# ESP32-H21 register map
Vendor: ESPRESSIF SYSTEMS (SHANGHAI) CO., LTD.; Series: ESP32 H-Series; File version: 1
CPU: RV32IMAC r0p0, little endian, no MPU, no FPU, 0 interrupt priority bits
Address unit: 32 bits
Registers are 32-bit, read-write, reset 0x0 unless marked. A register's access mark holds for its fields unless they carry their own. Offsets are from the block's base; [hi:lo] are bit positions; {n}, {i} and the like mark numbered series.

## SPI0 (part 1 of 2) — SPI (Serial Peripheral Interface) Controller 0
Base 0x60002000
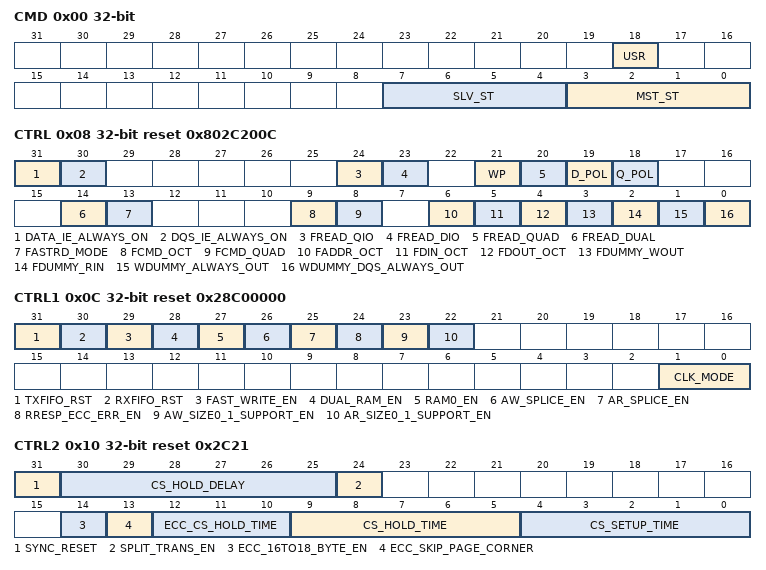
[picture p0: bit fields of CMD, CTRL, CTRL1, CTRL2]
0x00 CMD ro — SPI0 FSM status register
  [18] USR — SPI0 USR_CMD start bit, only used when SPI_MEM_AXI_REQ_EN is cleared. An operation will be triggered when the bit is set. The bit will be cleared once the operation done.1: enable 0: disable.
  [7:4] SLV_ST — The current status of SPI0 slave FSM: mspi_st. 0: idle state, 1: preparation state, 2: send command state, 3: send address state, 4: wait state, 5: read data state, 6:write data state, 7: done state, 8: read data end state.
  [3:0] MST_ST — The current status of SPI0 master FSM: spi0_mst_st. 0: idle state, 1:SPI0_GRANT , 2: program/erase suspend state, 3: SPI0 read data state, 4: wait cache/EDMA sent data is stored in SPI0 TX FIFO, 5: SPI0 write data state.
0x04 ADDR ro — SPI0 USR_CMD address register
  [31:0] USR_ADDR_VALUE — In SPI0 USR_CMD mode when SPI_MEM_USR is set, it is the memory address.
0x08 CTRL access per field reset 0x802C200C — SPI0 control register.
  [31] DATA_IE_ALWAYS_ON rw — When accesses to flash, 1: the IE signals of pads connected to SPI_IO[7:0] are always 1. 0: Others.
  [30] DQS_IE_ALWAYS_ON ro — When accesses to flash, 1: the IE signals of pads connected to SPI_DQS are always 1. 0: Others.
  [24] FREAD_QIO rw — In the read operations address phase and read-data phase apply 4 signals. 1: enable 0: disable.
  [23] FREAD_DIO rw — In the read operations address phase and read-data phase apply 2 signals. 1: enable 0: disable.
  [21] WP rw — Write protect signal output when SPI is idle. 1: output high, 0: output low.
  [20] FREAD_QUAD rw — In the read operations read-data phase apply 4 signals. 1: enable 0: disable.
  [19] D_POL rw — The bit is used to set MOSI line polarity, 1: high 0, low
  [18] Q_POL rw — The bit is used to set MISO line polarity, 1: high 0, low
  [14] FREAD_DUAL rw — In the read operations, read-data phase apply 2 signals. 1: enable 0: disable.
  [13] FASTRD_MODE rw — This bit enable the bits: SPI_MEM_FREAD_QIO, SPI_MEM_FREAD_DIO, SPI_MEM_FREAD_QOUT and SPI_MEM_FREAD_DOUT. 1: enable 0: disable.
  [9] FCMD_OCT ro — Apply 8 signals during command phase 1:enable 0: disable
  [8] FCMD_QUAD rw — Apply 4 signals during command phase 1:enable 0: disable
  [6] FADDR_OCT ro — Apply 8 signals during address phase 1:enable 0: disable
  [5] FDIN_OCT ro — Apply 8 signals during read-data phase 1:enable 0: disable
  [4] FDOUT_OCT ro — Apply 8 signals during write-data phase 1:enable 0: disable
  [3] FDUMMY_WOUT rw — In an MSPI write data transfer when accesses to flash, the level of SPI_IO[7:0] is output by the MSPI controller in the second half part of dummy phase. It is used to pre-drive flash.
  [2] FDUMMY_RIN rw — In an MSPI read data transfer when accesses to flash, the level of SPI_IO[7:0] is output by the MSPI controller in the first half part of dummy phase. It is used to mask invalid SPI_DQS in the half part of dummy phase.
  [1] WDUMMY_ALWAYS_OUT rw — In the dummy phase of an MSPI write data transfer when accesses to flash, the level of SPI_IO[7:0] is output by the MSPI controller.
  [0] WDUMMY_DQS_ALWAYS_OUT ro — In the dummy phase of an MSPI write data transfer when accesses to flash, the level of SPI_DQS is output by the MSPI controller.
0x0C CTRL1 access per field reset 0x28C00000 — SPI0 control1 register.
  [31] TXFIFO_RST wo — The synchronous reset signal for SPI0 TX AFIFO and all the AES_MSPI SYNC FIFO to send signals to AXI. Set this bit to reset these FIFO.
  [30] RXFIFO_RST wo — The synchronous reset signal for SPI0 RX AFIFO and all the AES_MSPI SYNC FIFO to receive signals from AXI. Set this bit to reset these FIFO.
  [29] FAST_WRITE_EN rw — Set this bit to write data faster, do not wait write data has been stored in tx_bus_fifo_l2. It will wait 4*T_clk_ctrl to insure the write data has been stored in tx_bus_fifo_l2.
  [28] DUAL_RAM_EN ro — Set this bit to enable DUAL-RAM mode, EXT_RAM0 and EXT_RAM1 will be accessed at the same time.
  [27] RAM0_EN ro — When SPI_MEM_DUAL_RAM_EN is 0 and SPI_MEM_RAM0_EN is 1, only EXT_RAM0 will be accessed. When SPI_MEM_DUAL_RAM_EN is 0 and SPI_MEM_RAM0_EN is 0, only EXT_RAM1 will be accessed. When SPI_MEM_DUAL_RAM_EN is 1, EXT_RAM0 and EXT_RAM1 will be accessed at the same time.
  [26] AW_SPLICE_EN ro — Set this bit to enable AXI Write Splice-transfer.
  [25] AR_SPLICE_EN ro — Set this bit to enable AXI Read Splice-transfer.
  [24] RRESP_ECC_ERR_EN rw — 1: RRESP is SLV_ERR when there is a ECC error in AXI read data. 0: RRESP is OKAY when there is a ECC error in AXI read data. The ECC error information is recorded in SPI_MEM_ECC_ERR_ADDR_REG.
  [23] AW_SIZE0_1_SUPPORT_EN rw — 1: MSPI supports AWSIZE 0~3. 0: When AWSIZE 0~1, MSPI reply SLV_ERR.
  [22] AR_SIZE0_1_SUPPORT_EN rw — 1: MSPI supports ARSIZE 0~3. When ARSIZE =0~2, MSPI read address is 4*n and reply the real AXI read data back. 0: When ARSIZE 0~1, MSPI reply SLV_ERR.
  [1:0] CLK_MODE rw — SPI clock mode bits. 0: SPI clock is off when CS inactive 1: SPI clock is delayed one cycle after CS inactive 2: SPI clock is delayed two cycles after CS inactive 3: SPI clock is alwasy on.
0x10 CTRL2 access per field reset 0x2C21 — SPI0 control2 register.
  [31] SYNC_RESET wo — The spi0_mst_st and spi0_slv_st will be reset.
  [30:25] CS_HOLD_DELAY rw — These bits are used to set the minimum CS high time tSHSL between SPI burst transfer when accesses to flash. tSHSL is (SPI_MEM_CS_HOLD_DELAY[5:0] + 1) MSPI core clock cycles.
  [24] SPLIT_TRANS_EN ro — Set this bit to enable SPI0 split one AXI read flash transfer into two SPI transfers when one transfer will cross flash or EXT_RAM page corner, valid no matter whether there is an ECC region or not.
  [14] ECC_16TO18_BYTE_EN ro — Set this bit to enable SPI0 and SPI1 ECC 16 bytes data with 2 ECC bytes mode when accesses flash.
  [13] ECC_SKIP_PAGE_CORNER ro — 1: SPI0 and SPI1 skip page corner when accesses flash. 0: Not skip page corner when accesses flash.
  [12:10] ECC_CS_HOLD_TIME ro — SPI_MEM_CS_HOLD_TIME + SPI_MEM_ECC_CS_HOLD_TIME is the SPI0 CS hold cycle in ECC mode when accessed flash.
  [9:5] CS_HOLD_TIME rw — SPI CS signal is delayed to inactive by SPI bus clock, this bits are combined with SPI_MEM_CS_HOLD bit.
  [4:0] CS_SETUP_TIME rw — (cycles-1) of prepare phase by SPI Bus clock, this bits are combined with SPI_MEM_CS_SETUP bit.
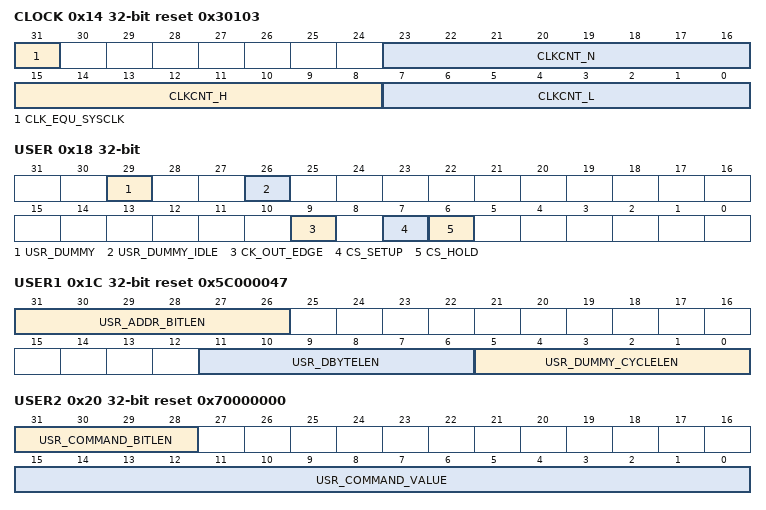
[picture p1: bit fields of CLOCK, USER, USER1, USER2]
0x14 CLOCK reset 0x30103 — SPI clock division control register.
  [31] CLK_EQU_SYSCLK — 1: 1-division mode, the frequency of SPI bus clock equals to that of MSPI module clock.
  [23:16] CLKCNT_N — In the master mode it is the divider of spi_mem_clk. So spi_mem_clk frequency is system/(SPI_MEM_CLKCNT_N+1)
  [15:8] CLKCNT_H — In the master mode it must be floor((SPI_MEM_CLKCNT_N+1)/2-1).
  [7:0] CLKCNT_L — In the master mode it must be equal to SPI_MEM_CLKCNT_N.
0x18 USER — SPI0 user register.
  [29] USR_DUMMY — This bit enable the dummy phase of an operation.
  [26] USR_DUMMY_IDLE — spi clock is disable in dummy phase when the bit is enable.
  [9] CK_OUT_EDGE — The bit combined with SPI_MEM_CK_IDLE_EDGE bit to control SPI clock mode 0~3.
  [7] CS_SETUP — spi cs is enable when spi is in prepare phase. 1: enable 0: disable.
  [6] CS_HOLD — spi cs keep low when spi is in done phase. 1: enable 0: disable.
0x1C USER1 access per field reset 0x5C000047 — SPI0 user1 register.
  [31:26] USR_ADDR_BITLEN rw — The length in bits of address phase. The register value shall be (bit_num-1).
  [11:6] USR_DBYTELEN ro — SPI0 USR_CMD read or write data byte length -1
  [5:0] USR_DUMMY_CYCLELEN rw — The length in spi_mem_clk cycles of dummy phase. The register value shall be (cycle_num-1).
0x20 USER2 reset 0x70000000 — SPI0 user2 register.
  [31:28] USR_COMMAND_BITLEN — The length in bits of command phase. The register value shall be (bit_num-1)
  [15:0] USR_COMMAND_VALUE — The value of command.
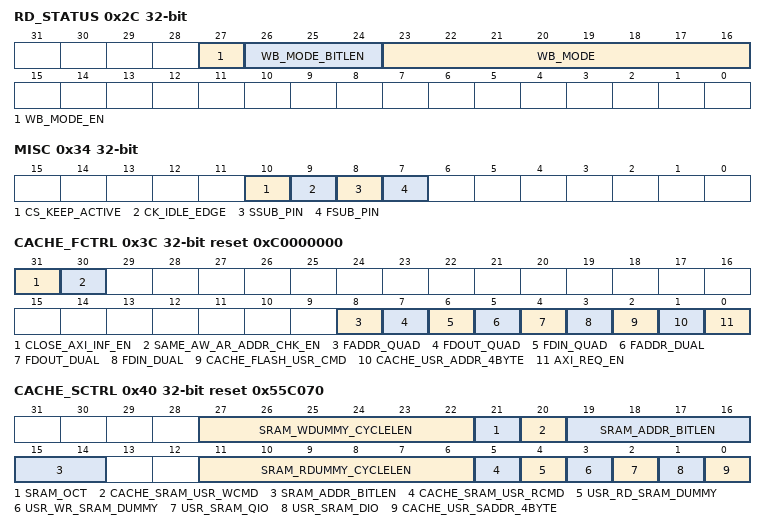
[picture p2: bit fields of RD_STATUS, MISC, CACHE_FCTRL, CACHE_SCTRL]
0x2C RD_STATUS — SPI0 read control register.
  [27] WB_MODE_EN — Mode bits is valid while this bit is enable. 1: enable 0: disable.
  [26:24] WB_MODE_BITLEN — Mode bits length for flash fast read mode.
  [23:16] WB_MODE — Mode bits in the flash fast read mode it is combined with spi_mem_fastrd_mode bit.
0x34 MISC access per field — SPI0 misc register
  [10] CS_KEEP_ACTIVE rw — SPI_CS line keep low when the bit is set.
  [9] CK_IDLE_EDGE rw — 1: SPI_CLK line is high when idle 0: spi clk line is low when idle
  [8] SSUB_PIN ro — For SPI0, sram is connected to SUBPINs.
  [7] FSUB_PIN ro — For SPI0, flash is connected to SUBPINs.
0x3C CACHE_FCTRL access per field reset 0xC0000000 — SPI0 bit mode control register.
  [31] CLOSE_AXI_INF_EN rw — Set this bit to close AXI read/write transfer to MSPI, which means that only SLV_ERR will be replied to BRESP/RRESP.
  [30] SAME_AW_AR_ADDR_CHK_EN ro — Set this bit to check AXI read/write the same address region.
  [8] FADDR_QUAD rw — For SPI0 flash, address phase apply 4 signals. 1: enable 0: disable. The bit is the same with spi_mem_fread_qio.
  [7] FDOUT_QUAD rw — For SPI0 flash, dout phase apply 4 signals. 1: enable 0: disable. The bit is the same with spi_mem_fread_qio.
  [6] FDIN_QUAD rw — For SPI0 flash, din phase apply 4 signals. 1: enable 0: disable. The bit is the same with spi_mem_fread_qio.
  [5] FADDR_DUAL rw — For SPI0 flash, address phase apply 2 signals. 1: enable 0: disable. The bit is the same with spi_mem_fread_dio.
  [4] FDOUT_DUAL rw — For SPI0 flash, dout phase apply 2 signals. 1: enable 0: disable. The bit is the same with spi_mem_fread_dio.
  [3] FDIN_DUAL rw — For SPI0 flash, din phase apply 2 signals. 1: enable 0: disable. The bit is the same with spi_mem_fread_dio.
  [2] CACHE_FLASH_USR_CMD rw — For SPI0, cache read flash for user define command, 1: enable, 0:disable.
  [1] CACHE_USR_ADDR_4BYTE rw — For SPI0, cache read flash with 4 bytes address, 1: enable, 0:disable.
  [0] AXI_REQ_EN rw — For SPI0, AXI master access enable, 1: enable, 0:disable.
0x40 CACHE_SCTRL ro reset 0x55C070 — SPI0 external RAM control register
  [27:22] SRAM_WDUMMY_CYCLELEN — For SPI0, In the external RAM mode, it is the length in bits of write dummy phase. The register value shall be (bit_num-1).
  [21] SRAM_OCT — reserved
  [20] CACHE_SRAM_USR_WCMD — For SPI0, In the external RAM mode cache write sram for user define command
  [19:14] SRAM_ADDR_BITLEN — For SPI0, In the external RAM mode, it is the length in bits of address phase. The register value shall be (bit_num-1).
  [11:6] SRAM_RDUMMY_CYCLELEN — For SPI0, In the external RAM mode, it is the length in bits of read dummy phase. The register value shall be (bit_num-1).
  [5] CACHE_SRAM_USR_RCMD — For SPI0, In the external RAM mode cache read external RAM for user define command.
  [4] USR_RD_SRAM_DUMMY — For SPI0, In the external RAM mode, it is the enable bit of dummy phase for read operations.
  [3] USR_WR_SRAM_DUMMY — For SPI0, In the external RAM mode, it is the enable bit of dummy phase for write operations.
  [2] USR_SRAM_QIO — For SPI0, In the external RAM mode, spi quad I/O mode enable, 1: enable, 0:disable
  [1] USR_SRAM_DIO — For SPI0, In the external RAM mode, spi dual I/O mode enable, 1: enable, 0:disable
  [0] CACHE_USR_SADDR_4BYTE — For SPI0, In the external RAM mode, cache read flash with 4 bytes command, 1: enable, 0:disable.
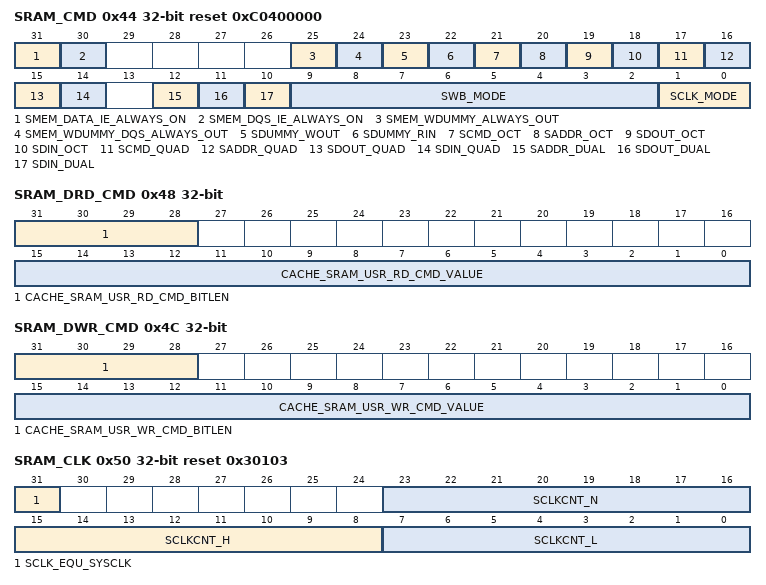
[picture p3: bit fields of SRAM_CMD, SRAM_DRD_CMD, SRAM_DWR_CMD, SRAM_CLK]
0x44 SRAM_CMD access per field reset 0xC0400000 — SPI0 external RAM mode control register
  [31] SMEM_DATA_IE_ALWAYS_ON ro — When accesses to external RAM, 1: the IE signals of pads connected to SPI_IO[7:0] are always 1. 0: Others.
  [30] SMEM_DQS_IE_ALWAYS_ON ro — When accesses to external RAM, 1: the IE signals of pads connected to SPI_DQS are always 1. 0: Others.
  [25] SMEM_WDUMMY_ALWAYS_OUT ro — In the dummy phase of an MSPI write data transfer when accesses to external RAM, the level of SPI_IO[7:0] is output by the MSPI controller.
  [24] SMEM_WDUMMY_DQS_ALWAYS_OUT ro — In the dummy phase of an MSPI write data transfer when accesses to external RAM, the level of SPI_DQS is output by the MSPI controller.
  [23] SDUMMY_WOUT ro — In the dummy phase of a MSPI write data transfer when accesses to external RAM, the signal level of SPI bus is output by the MSPI controller.
  [22] SDUMMY_RIN rw — In the dummy phase of a MSPI read data transfer when accesses to external RAM, the signal level of SPI bus is output by the MSPI controller.
  [21] SCMD_OCT ro — For SPI0 external RAM , cmd phase apply 8 signals. 1: enable 0: disable.
  [20] SADDR_OCT ro — For SPI0 external RAM , address phase apply 4 signals. 1: enable 0: disable.
  [19] SDOUT_OCT ro — For SPI0 external RAM , dout phase apply 8 signals. 1: enable 0: disable.
  [18] SDIN_OCT ro — For SPI0 external RAM , din phase apply 8 signals. 1: enable 0: disable.
  [17] SCMD_QUAD ro — For SPI0 external RAM , cmd phase apply 4 signals. 1: enable 0: disable. The bit is the same with spi_mem_usr_sram_qio.
  [16] SADDR_QUAD ro — For SPI0 external RAM , address phase apply 4 signals. 1: enable 0: disable. The bit is the same with spi_mem_usr_sram_qio.
  [15] SDOUT_QUAD ro — For SPI0 external RAM , dout phase apply 4 signals. 1: enable 0: disable. The bit is the same with spi_mem_usr_sram_qio.
  [14] SDIN_QUAD ro — For SPI0 external RAM , din phase apply 4 signals. 1: enable 0: disable. The bit is the same with spi_mem_usr_sram_qio.
  [12] SADDR_DUAL ro — For SPI0 external RAM , address phase apply 2 signals. 1: enable 0: disable. The bit is the same with spi_mem_usr_sram_dio.
  [11] SDOUT_DUAL ro — For SPI0 external RAM , dout phase apply 2 signals. 1: enable 0: disable. The bit is the same with spi_mem_usr_sram_dio.
  [10] SDIN_DUAL ro — For SPI0 external RAM , din phase apply 2 signals. 1: enable 0: disable. The bit is the same with spi_mem_usr_sram_dio.
  [9:2] SWB_MODE ro — Mode bits in the external RAM fast read mode it is combined with spi_mem_fastrd_mode bit.
  [1:0] SCLK_MODE ro — SPI clock mode bits. 0: SPI clock is off when CS inactive 1: SPI clock is delayed one cycle after CS inactive 2: SPI clock is delayed two cycles after CS inactive 3: SPI clock is always on.
0x48 SRAM_DRD_CMD ro — SPI0 external RAM DDR read command control register
  [31:28] CACHE_SRAM_USR_RD_CMD_BITLEN — For SPI0,When cache mode is enable it is the length in bits of command phase for sram. The register value shall be (bit_num-1).
  [15:0] CACHE_SRAM_USR_RD_CMD_VALUE — For SPI0,When cache mode is enable it is the read command value of command phase for sram.
0x4C SRAM_DWR_CMD ro — SPI0 external RAM DDR write command control register
  [31:28] CACHE_SRAM_USR_WR_CMD_BITLEN — For SPI0,When cache mode is enable it is the in bits of command phase for sram. The register value shall be (bit_num-1).
  [15:0] CACHE_SRAM_USR_WR_CMD_VALUE — For SPI0,When cache mode is enable it is the write command value of command phase for sram.
0x50 SRAM_CLK ro reset 0x30103 — SPI0 external RAM clock control register
  [31] SCLK_EQU_SYSCLK — For SPI0 external RAM interface, 1: spi_mem_clk is eqaul to system 0: spi_mem_clk is divided from system clock.
  [23:16] SCLKCNT_N — For SPI0 external RAM interface, it is the divider of spi_mem_clk. So spi_mem_clk frequency is system/(SPI_MEM_SCLKCNT_N+1)
  [15:8] SCLKCNT_H — For SPI0 external RAM interface, it must be floor((SPI_MEM_SCLKCNT_N+1)/2-1).
  [7:0] SCLKCNT_L — For SPI0 external RAM interface, it must be equal to SPI_MEM_SCLKCNT_N.
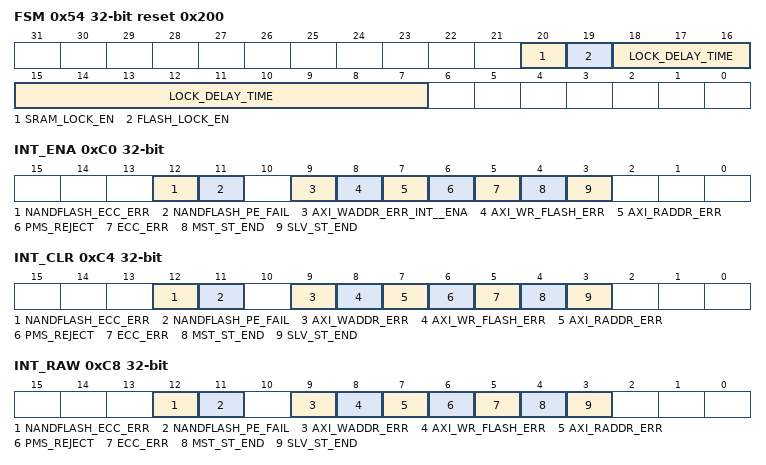
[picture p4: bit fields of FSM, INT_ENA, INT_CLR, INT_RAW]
0x54 FSM reset 0x200 — SPI0 FSM status register
  [20] SRAM_LOCK_EN — The lock enable for external RAM to lock spi0 trans req.1: Enable. 0: Disable.
  [19] FLASH_LOCK_EN — The lock enable for FLASH to lock spi0 trans req.1: Enable. 0: Disable.
  [18:7] LOCK_DELAY_TIME — The lock delay time of SPI0/1 arbiter by spi0_slv_st, after PER is sent by SPI1.
0xC0 INT_ENA access per field — SPI0 interrupt enable register
  [12] NANDFLASH_ECC_ERR ro — The enable bit for SPI_MEM_NANDFLASH_ECC_ERR_INT interrupt.
  [11] NANDFLASH_PE_FAIL ro — The enable bit for SPI_MEM_NANDFLASH_PE_FAIL_INT interrupt.
  [9] AXI_WADDR_ERR_INT__ENA ro — The enable bit for SPI_MEM_AXI_WADDR_ERR_INT interrupt.
  [8] AXI_WR_FLASH_ERR ro — The enable bit for SPI_MEM_AXI_WR_FALSH_ERR_INT interrupt.
  [7] AXI_RADDR_ERR rw — The enable bit for SPI_MEM_AXI_RADDR_ERR_INT interrupt.
  [6] PMS_REJECT rw — The enable bit for SPI_MEM_PMS_REJECT_INT interrupt.
  [5] ECC_ERR ro — The enable bit for SPI_MEM_ECC_ERR_INT interrupt.
  [4] MST_ST_END rw — The enable bit for SPI_MEM_MST_ST_END_INT interrupt.
  [3] SLV_ST_END rw — The enable bit for SPI_MEM_SLV_ST_END_INT interrupt.
0xC4 INT_CLR access per field — SPI0 interrupt clear register
  [12] NANDFLASH_ECC_ERR ro write-1-clears — The clear bit for SPI_MEM_NANDFLASH_ECC_ERR_INT interrupt.
  [11] NANDFLASH_PE_FAIL ro write-1-clears — The clear bit for SPI_MEM_NANDFLASH_PE_FAIL_INT interrupt.
  [9] AXI_WADDR_ERR ro write-1-clears — The clear bit for SPI_MEM_AXI_WADDR_ERR_INT interrupt.
  [8] AXI_WR_FLASH_ERR ro write-1-clears — The clear bit for SPI_MEM_AXI_WR_FALSH_ERR_INT interrupt.
  [7] AXI_RADDR_ERR wo write-1-clears — The clear bit for SPI_MEM_AXI_RADDR_ERR_INT interrupt.
  [6] PMS_REJECT wo write-1-clears — The clear bit for SPI_MEM_PMS_REJECT_INT interrupt.
  [5] ECC_ERR ro write-1-clears — The clear bit for SPI_MEM_ECC_ERR_INT interrupt.
  [4] MST_ST_END wo write-1-clears — The clear bit for SPI_MEM_MST_ST_END_INT interrupt.
  [3] SLV_ST_END wo write-1-clears — The clear bit for SPI_MEM_SLV_ST_END_INT interrupt.
0xC8 INT_RAW access per field — SPI0 interrupt raw register
  [12] NANDFLASH_ECC_ERR ro — The raw bit for SPI_MEM_NANDFLASH_ECC_ERR_INT interrupt. 1: Triggered when NAND FLASH SPI SEQ found ECCS bits is err when RDSR. 0: Others.
  [11] NANDFLASH_PE_FAIL ro — The raw bit for SPI_MEM_NANDFLASH_PE_FAIL_INT interrupt. 1: Triggered when NAND FLASH SPI SEQ found P/E_FAIL bits is err when RDSR. 0: Others.
  [9] AXI_WADDR_ERR ro — The raw bit for SPI_MEM_AXI_WADDR_ERR_INT interrupt. 1: Triggered when AXI write address is invalid by compared to MMU configuration. 0: Others.
  [8] AXI_WR_FLASH_ERR ro — The raw bit for SPI_MEM_AXI_WR_FALSH_ERR_INT interrupt. 1: Triggered when AXI write flash request is received. 0: Others.
  [7] AXI_RADDR_ERR rw — The raw bit for SPI_MEM_AXI_RADDR_ERR_INT interrupt. 1: Triggered when AXI read address is invalid by compared to MMU configuration. 0: Others.
  [6] PMS_REJECT rw — The raw bit for SPI_MEM_PMS_REJECT_INT interrupt. 1: Triggered when SPI1 access is rejected. 0: Others.
  [5] ECC_ERR ro — The raw bit for SPI_MEM_ECC_ERR_INT interrupt. When SPI_FMEM_ECC_ERR_INT_EN is set and SPI_SMEM_ECC_ERR_INT_EN is cleared, this bit is triggered when the error times of SPI0/1 ECC read flash are equal or bigger than SPI_MEM_ECC_ERR_INT_NUM. When SPI_FMEM_ECC_ERR_INT_EN is cleared and SPI_SMEM_ECC_ERR_INT_EN is set, this bit is triggered when the error times of SPI0/1 ECC read external RAM are equal or bigger than SPI_MEM_ECC_ERR_INT_NUM. When SPI_FMEM_ECC_ERR_INT_EN and SPI_SMEM_ECC_ERR_INT_EN are set, this bit is triggered when the total error times of SPI0/1 ECC read external RAM and flash are equal or bigger than SPI_MEM_ECC_ERR_INT_NUM. When SPI_FMEM_ECC_ERR_INT_EN and SPI_SMEM_ECC_ERR_INT_EN are cleared, this bit will not be triggered.
  [4] MST_ST_END rw — The raw bit for SPI_MEM_MST_ST_END_INT interrupt. 1: Triggered when spi0_mst_st is changed from non idle state to idle state. 0: Others.
  [3] SLV_ST_END rw — The raw bit for SPI_MEM_SLV_ST_END_INT interrupt. 1: Triggered when spi0_slv_st is changed from non idle state to idle state. It means that SPI_CS raises high. 0: Others
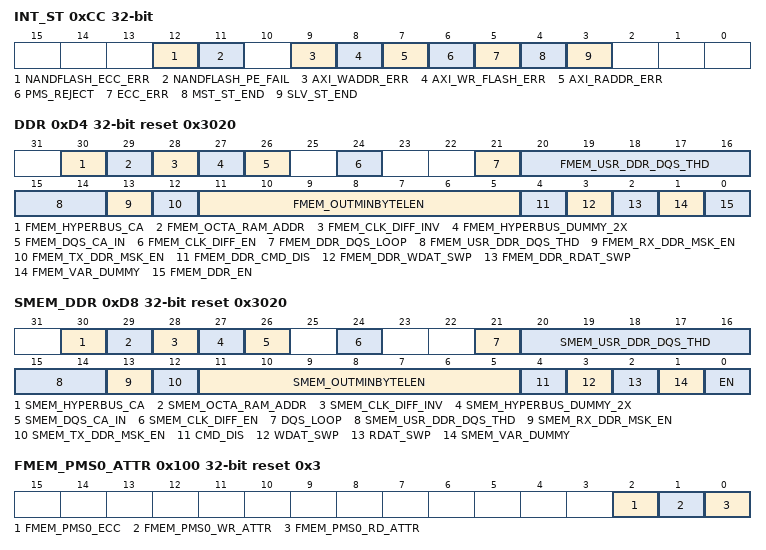
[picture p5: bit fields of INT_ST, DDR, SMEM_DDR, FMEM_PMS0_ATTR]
0xCC INT_ST ro — SPI0 interrupt status register
  [12] NANDFLASH_ECC_ERR — The status bit for SPI_MEM_NANDFLASH_ECC_ERR_INT interrupt.
  [11] NANDFLASH_PE_FAIL — The status bit for SPI_MEM_NANDFLASH_PE_FAIL_INT interrupt.
  [9] AXI_WADDR_ERR — The status bit for SPI_MEM_AXI_WADDR_ERR_INT interrupt.
  [8] AXI_WR_FLASH_ERR — The status bit for SPI_MEM_AXI_WR_FALSH_ERR_INT interrupt.
  [7] AXI_RADDR_ERR — The status bit for SPI_MEM_AXI_RADDR_ERR_INT interrupt.
  [6] PMS_REJECT — The status bit for SPI_MEM_PMS_REJECT_INT interrupt.
  [5] ECC_ERR — The status bit for SPI_MEM_ECC_ERR_INT interrupt.
  [4] MST_ST_END — The status bit for SPI_MEM_MST_ST_END_INT interrupt.
  [3] SLV_ST_END — The status bit for SPI_MEM_SLV_ST_END_INT interrupt.
0xD4 DDR ro reset 0x3020 — SPI0 flash DDR mode control register
  [30] FMEM_HYPERBUS_CA — Set this bit to enable HyperRAM address out when accesses to flash, which means ADDR_OUT[31:0] = {spi_usr_addr_value[19:4], 13'd0, spi_usr_addr_value[3:1]}.
  [29] FMEM_OCTA_RAM_ADDR — Set this bit to enable octa_ram address out when accesses to flash, which means ADDR_OUT[31:0] = {spi_usr_addr_value[25:4], 6'd0, spi_usr_addr_value[3:1], 1'b0}.
  [28] FMEM_CLK_DIFF_INV — Set this bit to invert SPI_DIFF when accesses to flash. .
  [27] FMEM_HYPERBUS_DUMMY_2X — Set this bit to enable the vary dummy function in SPI HyperBus mode, when SPI0 accesses flash or SPI1 accesses flash or sram.
  [26] FMEM_DQS_CA_IN — Set this bit to enable the input of SPI_DQS signal in SPI phases of CMD and ADDR.
  [24] FMEM_CLK_DIFF_EN — Set this bit to enable the differential SPI_CLK#.
  [21] FMEM_DDR_DQS_LOOP — 1: Do not need the input of SPI_DQS signal, SPI0 starts to receive data when spi0_slv_st is in SPI_MEM_DIN state. It is used when there is no SPI_DQS signal or SPI_DQS signal is not stable. 0: SPI0 starts to store data at the positive and negative edge of SPI_DQS.
  [20:14] FMEM_USR_DDR_DQS_THD — The delay number of data strobe which from memory based on SPI clock.
  [13] FMEM_RX_DDR_MSK_EN — Set this bit to mask the first or the last byte in SPI0 ECC DDR read mode, when accesses to flash.
  [12] FMEM_TX_DDR_MSK_EN — Set this bit to mask the first or the last byte in SPI0 ECC DDR write mode, when accesses to flash.
  [11:5] FMEM_OUTMINBYTELEN — It is the minimum output data length in the panda device.
  [4] FMEM_DDR_CMD_DIS — the bit is used to disable dual edge in command phase when DDR mode.
  [3] FMEM_DDR_WDAT_SWP — Set the bit to reorder tx data of the word in spi DDR mode.
  [2] FMEM_DDR_RDAT_SWP — Set the bit to reorder rx data of the word in spi DDR mode.
  [1] FMEM_VAR_DUMMY — Set the bit to enable variable dummy cycle in spi DDR mode.
  [0] FMEM_DDR_EN — 1: in DDR mode, 0 in SDR mode
0xD8 SMEM_DDR ro reset 0x3020 — SPI0 external RAM DDR mode control register
  [30] SMEM_HYPERBUS_CA — Set this bit to enable HyperRAM address out when accesses to external RAM, which means ADDR_OUT[31:0] = {spi_usr_addr_value[19:4], 13'd0, spi_usr_addr_value[3:1]}.
  [29] SMEM_OCTA_RAM_ADDR — Set this bit to enable octa_ram address out when accesses to external RAM, which means ADDR_OUT[31:0] = {spi_usr_addr_value[25:4], 6'd0, spi_usr_addr_value[3:1], 1'b0}.
  [28] SMEM_CLK_DIFF_INV — Set this bit to invert SPI_DIFF when accesses to external RAM. .
  [27] SMEM_HYPERBUS_DUMMY_2X — Set this bit to enable the vary dummy function in SPI HyperBus mode, when SPI0 accesses flash or SPI1 accesses flash or sram.
  [26] SMEM_DQS_CA_IN — Set this bit to enable the input of SPI_DQS signal in SPI phases of CMD and ADDR.
  [24] SMEM_CLK_DIFF_EN — Set this bit to enable the differential SPI_CLK#.
  [21] DQS_LOOP — 1: Do not need the input of SPI_DQS signal, SPI0 starts to receive data when spi0_slv_st is in SPI_MEM_DIN state. It is used when there is no SPI_DQS signal or SPI_DQS signal is not stable. 0: SPI0 starts to store data at the positive and negative edge of SPI_DQS.
  [20:14] SMEM_USR_DDR_DQS_THD — The delay number of data strobe which from memory based on SPI clock.
  [13] SMEM_RX_DDR_MSK_EN — Set this bit to mask the first or the last byte in SPI0 ECC DDR read mode, when accesses to external RAM.
  [12] SMEM_TX_DDR_MSK_EN — Set this bit to mask the first or the last byte in SPI0 ECC DDR write mode, when accesses to external RAM.
  [11:5] SMEM_OUTMINBYTELEN — It is the minimum output data length in the DDR psram.
  [4] CMD_DIS — the bit is used to disable dual edge in command phase when DDR mode.
  [3] WDAT_SWP — Set the bit to reorder tx data of the word in spi DDR mode.
  [2] RDAT_SWP — Set the bit to reorder rx data of the word in spi DDR mode.
  [1] SMEM_VAR_DUMMY — Set the bit to enable variable dummy cycle in spi DDR mode.
  [0] EN — 1: in DDR mode, 0 in SDR mode
0x100 FMEM_PMS0_ATTR reset 0x3 — MSPI flash PMS section $n attribute register
  [2] FMEM_PMS0_ECC — SPI1 flash PMS section 0 ECC mode, 1: enable ECC mode. 0: Disable it. The flash PMS section 0 is configured by registers SPI_FMEM_PMS0_ADDR_REG and SPI_FMEM_PMS0_SIZE_REG.
  [1] FMEM_PMS0_WR_ATTR — 1: SPI1 flash PMS section 0 write accessible. 0: Not allowed.
  [0] FMEM_PMS0_RD_ATTR — 1: SPI1 flash PMS section 0 read accessible. 0: Not allowed.
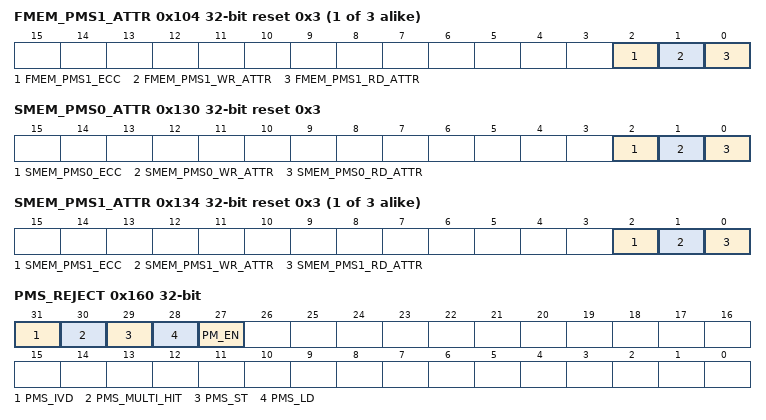
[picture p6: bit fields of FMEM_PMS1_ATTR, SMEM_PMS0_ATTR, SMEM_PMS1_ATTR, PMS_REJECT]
{0x100+4i} FMEM_PMS{i}_ATTR reset 0x3 (i=1..3) — SPI1 flash PMS section $n attribute register
  [2] FMEM_PMS{i}_ECC — SPI1 flash PMS section {i} ECC mode, 1: enable ECC mode. 0: Disable it. The flash PMS section {i} is configured by registers SPI_FMEM_PMS{i}_ADDR_REG and SPI_FMEM_PMS{i}_SIZE_REG.
  [1] FMEM_PMS{i}_WR_ATTR — 1: SPI1 flash PMS section {i} write accessible. 0: Not allowed.
  [0] FMEM_PMS{i}_RD_ATTR — 1: SPI1 flash PMS section {i} read accessible. 0: Not allowed.
{0x110+4i} FMEM_PMS{i}_ADDR (i=0..3) — SPI1 flash PMS section {i} start address register
  [28:0] S — SPI1 flash PMS section %s start address value
{0x120+4i} FMEM_PMS{i}_SIZE (i=0..3) reset 0x1000 — SPI1 flash PMS section {i} start address register
  [16:0] FMEM_PMS_SIZE — SPI1 flash PMS section %s address region is (SPI_FMEM_PMS%s_ADDR_S, SPI_FMEM_PMS%s_ADDR_S + SPI_FMEM_PMS%s_SIZE)
0x130 SMEM_PMS0_ATTR reset 0x3 — SPI1 flash PMS section $n start address register
  [2] SMEM_PMS0_ECC — SPI1 external RAM PMS section 0 ECC mode, 1: enable ECC mode. 0: Disable it. The external RAM PMS section 0 is configured by registers SPI_SMEM_PMS0_ADDR_REG and SPI_SMEM_PMS0_SIZE_REG.
  [1] SMEM_PMS0_WR_ATTR — 1: SPI1 external RAM PMS section 0 write accessible. 0: Not allowed.
  [0] SMEM_PMS0_RD_ATTR — 1: SPI1 external RAM PMS section 0 read accessible. 0: Not allowed.
{0x130+4i} SMEM_PMS{i}_ATTR reset 0x3 (i=1..3) — SPI1 external RAM PMS section $n attribute register
  [2] SMEM_PMS{i}_ECC — SPI1 external RAM PMS section {i} ECC mode, 1: enable ECC mode. 0: Disable it. The external RAM PMS section {i} is configured by registers SPI_SMEM_PMS{i}_ADDR_REG and SPI_SMEM_PMS{i}_SIZE_REG.
  [1] SMEM_PMS{i}_WR_ATTR — 1: SPI1 external RAM PMS section {i} write accessible. 0: Not allowed.
  [0] SMEM_PMS{i}_RD_ATTR — 1: SPI1 external RAM PMS section {i} read accessible. 0: Not allowed.
{0x140+4i} SMEM_PMS{i}_ADDR (i=0..3) ro — SPI1 external RAM PMS section {i} start address register
  [28:0] S — SPI1 external RAM PMS section %s start address value
{0x150+4i} SMEM_PMS{i}_SIZE (i=0..3) ro reset 0x1000 — SPI1 external RAM PMS section {i} start address register
  [16:0] SMEM_PMS_SIZE — SPI1 external RAM PMS section %s address region is (SPI_SMEM_PMS%s_ADDR_S, SPI_SMEM_PMS%s_ADDR_S + SPI_SMEM_PMS%s_SIZE)
0x160 PMS_REJECT access per field — SPI1 access reject register
  [31] PMS_IVD ro — 1: SPI1 access is rejected because of address multi-hit. 0: No address multi-hit error. It is cleared by when SPI_MEM_PMS_REJECT_INT_CLR bit is set.
  [30] PMS_MULTI_HIT ro — 1: SPI1 access is rejected because of address miss. 0: No address miss error. It is cleared by when SPI_MEM_PMS_REJECT_INT_CLR bit is set.
  [29] PMS_ST ro — 1: SPI1 read access error. 0: No read access error. It is cleared by when SPI_MEM_PMS_REJECT_INT_CLR bit is set.
  [28] PMS_LD ro — 1: SPI1 write access error. 0: No write access error. It is cleared by when SPI_MEM_PMS_REJECT_INT_CLR bit is set.
  [27] PM_EN rw — Set this bit to enable SPI0/1 transfer permission control function.
0x164 PMS_REJECT_ADDR ro — SPI1 access reject addr register
  [28:0] REJECT_ADDR — This bits show the first SPI1 access error address. It is cleared by when SPI_MEM_PMS_REJECT_INT_CLR bit is set.
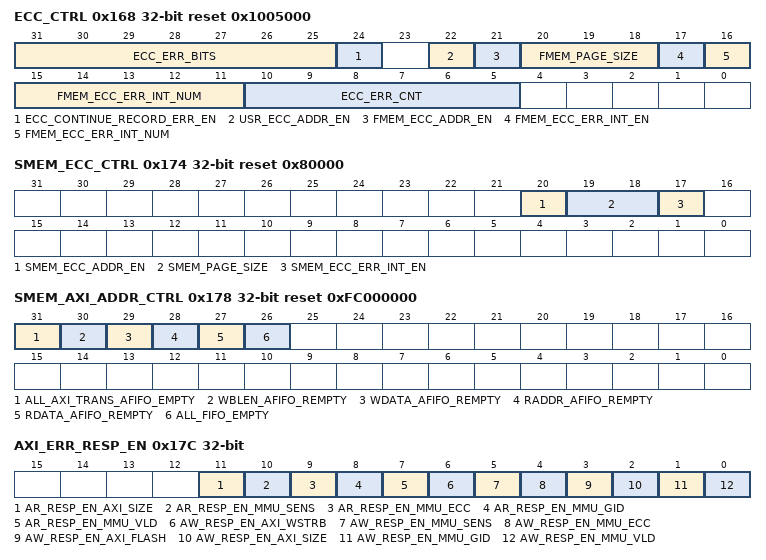
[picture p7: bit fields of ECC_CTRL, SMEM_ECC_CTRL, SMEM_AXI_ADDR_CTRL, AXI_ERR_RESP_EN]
0x168 ECC_CTRL access per field reset 0x1005000 — MSPI ECC control register
  [31:25] ECC_ERR_BITS ro — Records the first ECC error bit number in the 16 bytes(From 0~127, corresponding to byte 0 bit 0 to byte 15 bit 7)
  [24] ECC_CONTINUE_RECORD_ERR_EN ro — 1: The error information in SPI_MEM_ECC_ERR_BITS and SPI_MEM_ECC_ERR_ADDR is updated when there is an ECC error. 0: SPI_MEM_ECC_ERR_BITS and SPI_MEM_ECC_ERR_ADDR record the first ECC error information.
  [22] USR_ECC_ADDR_EN ro — Set this bit to enable ECC address convert in SPI0/1 USR_CMD transfer.
  [21] FMEM_ECC_ADDR_EN ro — Set this bit to enable MSPI ECC address conversion, no matter MSPI accesses to the ECC region or non-ECC region of flash. If there is no ECC region in flash, this bit should be 0. Otherwise, this bit should be 1.
  [20:18] FMEM_PAGE_SIZE rw — Set the page size of the flash accessed by MSPI. 0: 256 bytes. 1: 512 bytes. 2: 1024 bytes. 3: 2048 bytes. 4: 4096 bytes.
  [17] FMEM_ECC_ERR_INT_EN ro — Set this bit to calculate the error times of MSPI ECC read when accesses to flash.
  [16:11] FMEM_ECC_ERR_INT_NUM ro — Set the error times of MSPI ECC read to generate MSPI SPI_MEM_ECC_ERR_INT interrupt.
  [10:5] ECC_ERR_CNT ro — This bits show the error times of MSPI ECC read. It is cleared by when SPI_MEM_ECC_ERR_INT_CLR bit is set.
0x16C ECC_ERR_ADDR ro — MSPI ECC error address register
  [28:0] ECC_ERR_ADDR — This bits show the first MSPI ECC error address. It is cleared by when SPI_MEM_ECC_ERR_INT_CLR bit is set.
0x170 AXI_ERR_ADDR ro — SPI0 AXI request error address.
  [28:0] AXI_ERR_ADDR — This bits show the first AXI write/read invalid error or AXI write flash error address. It is cleared by when SPI_MEM_AXI_WADDR_ERR_INT_CLR, SPI_MEM_AXI_WR_FLASH_ERR_IN_CLR or SPI_MEM_AXI_RADDR_ERR_IN_CLR bit is set.
0x174 SMEM_ECC_CTRL ro reset 0x80000 — MSPI ECC control register
  [20] SMEM_ECC_ADDR_EN — Set this bit to enable MSPI ECC address conversion, no matter MSPI accesses to the ECC region or non-ECC region of external RAM. If there is no ECC region in external RAM, this bit should be 0. Otherwise, this bit should be 1.
  [19:18] SMEM_PAGE_SIZE — Set the page size of the external RAM accessed by MSPI. 0: 256 bytes. 1: 512 bytes. 2: 1024 bytes. 3: 2048 bytes.
  [17] SMEM_ECC_ERR_INT_EN — Set this bit to calculate the error times of MSPI ECC read when accesses to external RAM.
0x178 SMEM_AXI_ADDR_CTRL ro reset 0xFC000000 — SPI0 AXI address control register
  [31] ALL_AXI_TRANS_AFIFO_EMPTY — This bit is set when WADDR_AFIFO, WBLEN_AFIFO, WDATA_AFIFO, AXI_RADDR_CTL_AFIFO and RDATA_AFIFO are empty and spi0_mst_st is IDLE.
  [30] WBLEN_AFIFO_REMPTY — 1: WBLEN_AFIFO is empty. 0: At least one AXI write transfer is pending.
  [29] WDATA_AFIFO_REMPTY — 1: WDATA_AFIFO is empty. 0: At least one AXI write transfer is pending.
  [28] RADDR_AFIFO_REMPTY — 1: AXI_RADDR_CTL_AFIFO is empty. 0: At least one AXI read transfer is pending.
  [27] RDATA_AFIFO_REMPTY — 1: RDATA_AFIFO is empty. 0: At least one AXI read transfer is pending.
  [26] ALL_FIFO_EMPTY — The empty status of all AFIFO and SYNC_FIFO in MSPI module. 1: All AXI transfers and SPI0 transfers are done. 0: Others.
0x17C AXI_ERR_RESP_EN — SPI0 AXI error response enable register
  [11] AR_RESP_EN_AXI_SIZE — Set this bit to enable AXI response function for axi size err in axi read trans.
  [10] AR_RESP_EN_MMU_SENS — Set this bit to enable AXI response function for mmu sensitive err in axi read trans.
  [9] AR_RESP_EN_MMU_ECC — Set this bit to enable AXI response function for mmu ecc err in axi read trans.
  [8] AR_RESP_EN_MMU_GID — Set this bit to enable AXI response function for mmu gid err in axi read trans.
  [7] AR_RESP_EN_MMU_VLD — Set this bit to enable AXI response function for mmu valid err in axi read trans.
  [6] AW_RESP_EN_AXI_WSTRB — Set this bit to enable AXI response function for axi wstrb err in axi write trans.
  [5] AW_RESP_EN_MMU_SENS — Set this bit to enable AXI response function for mmu sens in err axi write trans.
  [4] AW_RESP_EN_MMU_ECC — Set this bit to enable AXI response function for mmu ecc err in axi write trans.
  [3] AW_RESP_EN_AXI_FLASH — Set this bit to enable AXI response function for axi flash err in axi write trans.
  [2] AW_RESP_EN_AXI_SIZE — Set this bit to enable AXI response function for axi size err in axi write trans.
  [1] AW_RESP_EN_MMU_GID — Set this bit to enable AXI response function for mmu gid err in axi write trans.
  [0] AW_RESP_EN_MMU_VLD — Set this bit to enable AXI response function for mmu valid err in axi write trans.
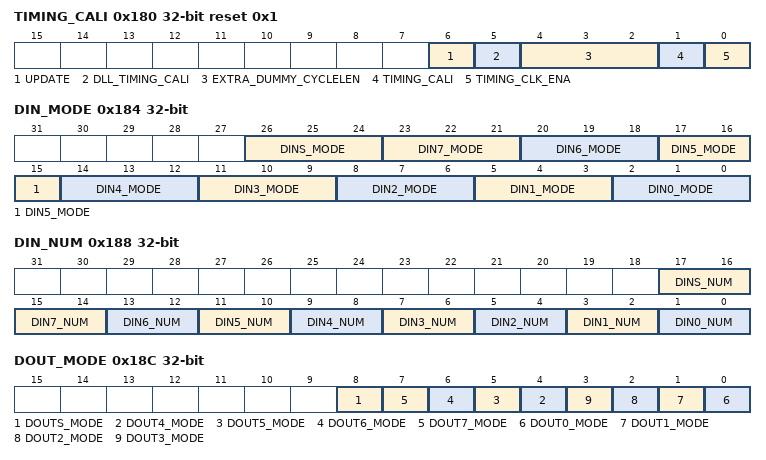
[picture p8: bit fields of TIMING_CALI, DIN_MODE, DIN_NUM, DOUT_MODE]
0x180 TIMING_CALI access per field reset 0x1 — SPI0 flash timing calibration register
  [6] UPDATE wo — Set this bit to update delay mode, delay num and extra dummy in MSPI.
  [5] DLL_TIMING_CALI ro — Set this bit to enable DLL for timing calibration in DDR mode when accessed to flash.
  [4:2] EXTRA_DUMMY_CYCLELEN rw — add extra dummy spi clock cycle length for spi clock calibration.
  [1] TIMING_CALI rw — The bit is used to enable timing auto-calibration for all reading operations.
  [0] TIMING_CLK_ENA rw — The bit is used to enable timing adjust clock for all reading operations.
0x184 DIN_MODE — MSPI flash input timing delay mode control register
  [26:24] DINS_MODE — the input signals are delayed by system clock cycles, 0: input without delayed, 1: input with the posedge of clk_apb,2 input with the negedge of clk_apb, 3: input with the spi_clk
  [3n+2:3n] DIN{n}_MODE (n=4..7) — the input signals are delayed by system clock cycles, 0: input without delayed, 1: input with the posedge of clk_apb,2 input with the negedge of clk_apb, 3: input with the spi_clk
  [3n+2:3n] DIN{n}_MODE (n=0..3) — the input signals are delayed by system clock cycles, 0: input without delayed, 1: input with the posedge of clk_apb,2 input with the negedge of clk_apb, 3: input with the posedge of clk_160, 4 input with the negedge of clk_160, 5: input with the spi_clk high edge, 6: input with the spi_clk low edge
0x188 DIN_NUM — MSPI flash input timing delay number control register
  [17:16] DINS_NUM — the input signals are delayed by system clock cycles, 0: delayed by 1 cycle, 1: delayed by 2 cycles,...
  [2n+1:2n] DIN{n}_NUM (n=0..7) — the input signals are delayed by system clock cycles, 0: delayed by 1 cycle, 1: delayed by 2 cycles,...
0x18C DOUT_MODE — MSPI flash output timing adjustment control register
  [8] DOUTS_MODE — the output signals are delayed by system clock cycles, 0: output without delayed, 1: output with the posedge of clk_apb,2 output with the negedge of clk_apb, 3: output with the spi_clk
  [n] DOUT{n}_MODE (n=4..7) — the output signals are delayed by system clock cycles, 0: output without delayed, 1: output with the posedge of clk_apb,2 output with the negedge of clk_apb, 3: output with the spi_clk
  [n] DOUT{n}_MODE (n=0..3) — the output signals are delayed by system clock cycles, 0: output without delayed, 1: output with the posedge of clk_apb,2 output with the negedge of clk_apb, 3: output with the posedge of clk_160,4 output with the negedge of clk_160,5: output with the spi_clk high edge ,6: output with the spi_clk low edge
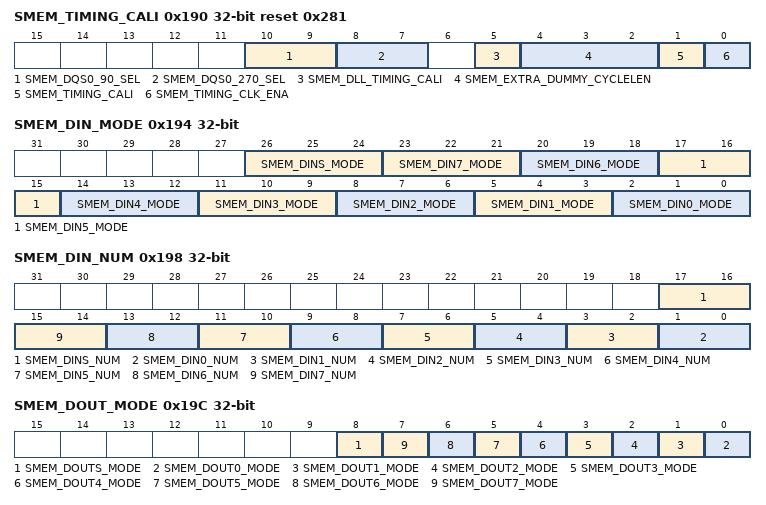
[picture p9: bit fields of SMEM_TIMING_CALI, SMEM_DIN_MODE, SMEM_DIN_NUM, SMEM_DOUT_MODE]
0x190 SMEM_TIMING_CALI ro reset 0x281 — MSPI external RAM timing calibration register
  [10:9] SMEM_DQS0_90_SEL — Set these bits to delay dqs signal for DLL timing adjust. 2'd0: 0.5ns, 2'd1: 1.0ns, 2'd2: 1.5ns 2'd3: 2.0ns.
  [8:7] SMEM_DQS0_270_SEL — Set these bits to delay dqs signal & invert delayed signal for DLL timing adjust. 2'd0: 0.5ns, 2'd1: 1.0ns, 2'd2: 1.5ns 2'd3: 2.0ns.
  [5] SMEM_DLL_TIMING_CALI — Set this bit to enable DLL for timing calibration in DDR mode when accessed to EXT_RAM.
  [4:2] SMEM_EXTRA_DUMMY_CYCLELEN — For sram, add extra dummy spi clock cycle length for spi clock calibration.
  [1] SMEM_TIMING_CALI — For sram, the bit is used to enable timing auto-calibration for all reading operations.
  [0] SMEM_TIMING_CLK_ENA — For sram, the bit is used to enable timing adjust clock for all reading operations.
0x194 SMEM_DIN_MODE ro — MSPI external RAM input timing delay mode control register
  [26:24] SMEM_DINS_MODE — the input signals are delayed by system clock cycles, 0: input without delayed, 1: input with the posedge of clk_apb,2 input with the negedge of clk_apb, 3: input with the posedge of clk_160, 4 input with the negedge of clk_160, 5: input with the spi_clk high edge, 6: input with the spi_clk low edge
  [3n+2:3n] SMEM_DIN{n}_MODE (n=0..7) — the input signals are delayed by system clock cycles, 0: input without delayed, 1: input with the posedge of clk_apb,2 input with the negedge of clk_apb, 3: input with the posedge of clk_160, 4 input with the negedge of clk_160, 5: input with the spi_clk high edge, 6: input with the spi_clk low edge
0x198 SMEM_DIN_NUM ro — MSPI external RAM input timing delay number control register
  [17:16] SMEM_DINS_NUM — the input signals are delayed by system clock cycles, 0: delayed by 1 cycle, 1: delayed by 2 cycles,...
  [2n+1:2n] SMEM_DIN{n}_NUM (n=0..7) — the input signals are delayed by system clock cycles, 0: delayed by 1 cycle, 1: delayed by 2 cycles,...
0x19C SMEM_DOUT_MODE ro — MSPI external RAM output timing adjustment control register
  [8] SMEM_DOUTS_MODE — the output signals are delayed by system clock cycles, 0: output without delayed, 1: output with the posedge of clk_apb,2 output with the negedge of clk_apb, 3: output with the posedge of clk_160,4 output with the negedge of clk_160,5: output with the spi_clk high edge ,6: output with the spi_clk low edge
  [n] SMEM_DOUT{n}_MODE (n=0..7) — the output signals are delayed by system clock cycles, 0: output without delayed, 1: output with the posedge of clk_apb,2 output with the negedge of clk_apb, 3: output with the posedge of clk_160,4 output with the negedge of clk_160,5: output with the spi_clk high edge ,6: output with the spi_clk low edge
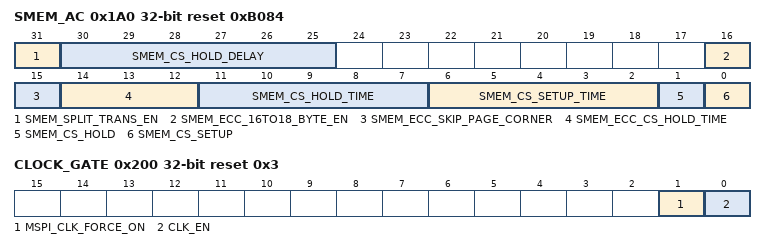
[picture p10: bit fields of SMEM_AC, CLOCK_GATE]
0x1A0 SMEM_AC ro reset 0xB084 — MSPI external RAM ECC and SPI CS timing control register
  [31] SMEM_SPLIT_TRANS_EN — Set this bit to enable SPI0 split one AXI accesses EXT_RAM transfer into two SPI transfers when one transfer will cross flash/EXT_RAM page corner, valid no matter whether there is an ECC region or not.
  [30:25] SMEM_CS_HOLD_DELAY — These bits are used to set the minimum CS high time tSHSL between SPI burst transfer when accesses to external RAM. tSHSL is (SPI_SMEM_CS_HOLD_DELAY[5:0] + 1) MSPI core clock cycles.
  [16] SMEM_ECC_16TO18_BYTE_EN — Set this bit to enable SPI0 and SPI1 ECC 16 bytes data with 2 ECC bytes mode when accesses external RAM.
  [15] SMEM_ECC_SKIP_PAGE_CORNER — 1: SPI0 skips page corner when accesses external RAM. 0: Not skip page corner when accesses external RAM.
  [14:12] SMEM_ECC_CS_HOLD_TIME — SPI_SMEM_CS_HOLD_TIME + SPI_SMEM_ECC_CS_HOLD_TIME is the SPI0 and SPI1 CS hold cycles in ECC mode when accessed external RAM.
  [11:7] SMEM_CS_HOLD_TIME — For SPI0 and SPI1, spi cs signal is delayed to inactive by spi clock this bits are combined with spi_mem_cs_hold bit.
  [6:2] SMEM_CS_SETUP_TIME — For spi0, (cycles-1) of prepare phase by spi clock this bits are combined with spi_mem_cs_setup bit.
  [1] SMEM_CS_HOLD — For SPI0 and SPI1, spi cs keep low when spi is in done phase. 1: enable 0: disable.
  [0] SMEM_CS_SETUP — For SPI0 and SPI1, spi cs is enable when spi is in prepare phase. 1: enable 0: disable.
0x200 CLOCK_GATE reset 0x3 — SPI0 clock gate register
  [1] MSPI_CLK_FORCE_ON — MSPI lowpower function clock gate force on signal. 1: Enable. 0: Disable.
  [0] CLK_EN — Register clock gate enable signal. 1: Enable. 0: Disable.
